# HDSC_HC32F480 register map
Vendor: HDSC Co.Ltd; Series: ARMCM4; File version: 1.2
CPU: CM0 r0p0, little endian, no MPU, no FPU, 3 interrupt priority bits
Registers are 16-bit, read-write, reset 0x0 unless marked. A register's access mark holds for its fields unless they carry their own. Offsets are from the block's base; [hi:lo] are bit positions; {n}, {i} and the like mark numbered series.

## EXMC
Base 0x40050000; alternate view of ETH
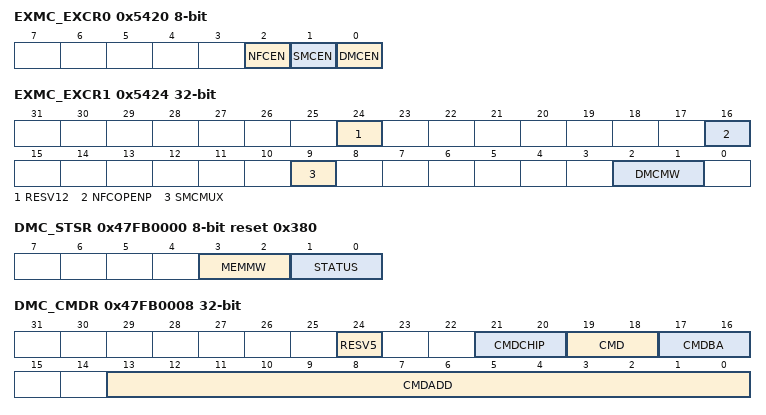
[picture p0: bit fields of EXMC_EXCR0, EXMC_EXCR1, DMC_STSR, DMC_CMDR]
0x5420 EXMC_EXCR0 8-bit
  [2] NFCEN, [1] SMCEN, [0] DMCEN
0x5424 EXMC_EXCR1 32-bit
  [24] RESV12, [16] NFCOPENP, [9] SMCMUX, [2:1] DMCMW
0x47FB0000 DMC_STSR 8-bit ro reset 0x380
  [3:2] MEMMW, [1:0] STATUS
0x47FB0004 DMC_STCR 8-bit wo
  [2:0] STCTL
0x47FB0008 DMC_CMDR 32-bit wo
  [24] RESV5 rw, [21:20] CMDCHIP, [19:18] CMD, [17:16] CMDBA, [13:0] CMDADD
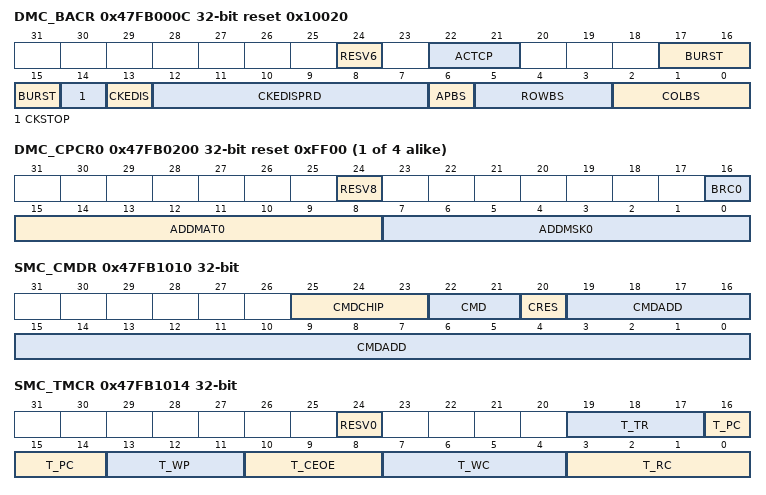
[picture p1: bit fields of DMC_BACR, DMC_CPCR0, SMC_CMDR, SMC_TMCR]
0x47FB000C DMC_BACR 32-bit reset 0x10020
  [24] RESV6, [22:21] ACTCP, [17:15] BURST, [14] CKSTOP, [13] CKEDIS, [12:7] CKEDISPRD, [6] APBS, [5:3] ROWBS, [2:0] COLBS
0x47FB0010 DMC_RFCR reset 0xA60
  [14:0] REFPRD
0x47FB0014 DMC_TMCR_T_CASL 8-bit reset 0x6
  [3:1] T_CASL
0x47FB0018 DMC_TMCR_T_DQSS 8-bit reset 0x1
  [1:0] T_DQSS
0x47FB001C DMC_TMCR_T_MRD 8-bit reset 0x2
  [6:0] T_MRD
0x47FB0020 DMC_TMCR_T_RAS 8-bit reset 0x7
  [3:0] T_RAS
0x47FB0024 DMC_TMCR_T_RC 8-bit reset 0xB
  [3:0] T_RC
0x47FB0028 DMC_TMCR_T_RCD 8-bit reset 0x1D
  [2:0] T_RCD
0x47FB002C DMC_TMCR_T_RFC 8-bit reset 0x212
  [4:0] T_RFC
0x47FB0030 DMC_TMCR_T_RP 8-bit reset 0x1D
  [2:0] T_RP
0x47FB0034 DMC_TMCR_T_RRD 8-bit reset 0x2
  [3:0] T_RRD
0x47FB0038 DMC_TMCR_T_WR 8-bit reset 0x3
  [2:0] T_WR
0x47FB003C DMC_TMCR_T_WTR 8-bit reset 0x2
  [2:0] T_WTR
0x47FB0040 DMC_TMCR_T_XP 8-bit reset 0x1
0x47FB0044 DMC_TMCR_T_XSR 8-bit reset 0xA
0x47FB0048 DMC_TMCR_T_ESR 8-bit reset 0x14
{0x47FB0200+4i} DMC_CPCR{i} 32-bit reset 0xFF00 (i=0..3)
  [24] RESV{i+8}, [16] BRC{i}, [15:8] ADDMAT{i}, [7:0] ADDMSK{i}
0x47FB0300 EXMC_EXSR1 8-bit ro
0x47FB1000 SMC_STSR 8-bit ro reset 0x1
  [0] STATUS
0x47FB1008 SMC_STCR0 8-bit wo
  [2] LPWIR
0x47FB100C SMC_STCR1 8-bit wo
  [2] LPWOR
0x47FB1010 SMC_CMDR 32-bit wo
  [25:23] CMDCHIP, [22:21] CMD, [20] CRES, [19:0] CMDADD
0x47FB1014 SMC_TMCR 32-bit wo
  [24] RESV0 rw, [19:17] T_TR, [16:14] T_PC, [13:11] T_WP, [10:8] T_CEOE, [7:4] T_WC, [3:0] T_RC
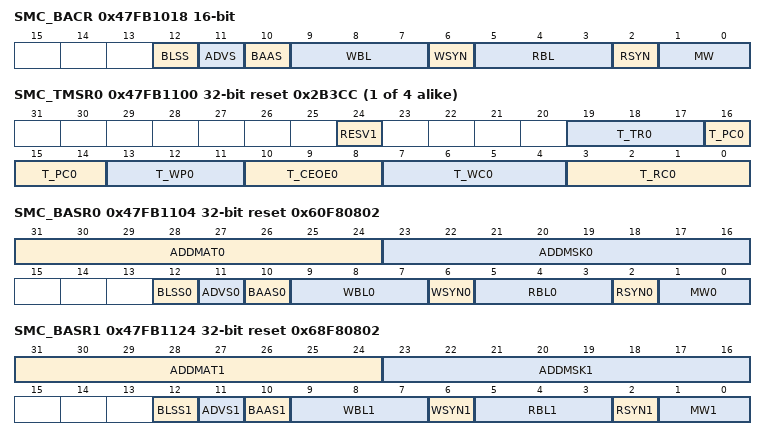
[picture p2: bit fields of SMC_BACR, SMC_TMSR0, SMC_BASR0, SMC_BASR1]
0x47FB1018 SMC_BACR wo
  [12] BLSS, [11] ADVS, [10] BAAS, [9:7] WBL, [6] WSYN, [5:3] RBL, [2] RSYN, [1:0] MW
0x47FB1020 SMC_RFCR 8-bit
  [3:0] REFPRD
{0x47FB1100+0x20*i} SMC_TMSR{i} 32-bit ro reset 0x2B3CC (i=0..3)
  [24] RESV{i+1} rw, [19:17] T_TR{i}, [16:14] T_PC{i}, [13:11] T_WP{i}, [10:8] T_CEOE{i}, [7:4] T_WC{i}, [3:0] T_RC{i}
0x47FB1104 SMC_BASR0 32-bit ro reset 0x60F80802
  [31:24] ADDMAT0, [23:16] ADDMSK0, [12] BLSS0, [11] ADVS0, [10] BAAS0, [9:7] WBL0, [6] WSYN0, [5:3] RBL0, [2] RSYN0, [1:0] MW0
0x47FB1124 SMC_BASR1 32-bit ro reset 0x68F80802
  [31:24] ADDMAT1, [23:16] ADDMSK1, [12] BLSS1, [11] ADVS1, [10] BAAS1, [9:7] WBL1, [6] WSYN1, [5:3] RBL1, [2] RSYN1, [1:0] MW1
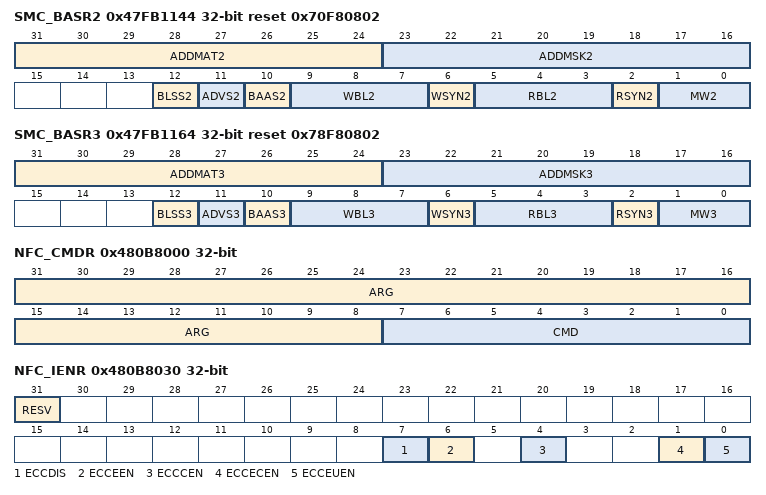
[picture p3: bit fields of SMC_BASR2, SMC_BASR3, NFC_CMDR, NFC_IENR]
0x47FB1144 SMC_BASR2 32-bit ro reset 0x70F80802
  [31:24] ADDMAT2, [23:16] ADDMSK2, [12] BLSS2, [11] ADVS2, [10] BAAS2, [9:7] WBL2, [6] WSYN2, [5:3] RBL2, [2] RSYN2, [1:0] MW2
0x47FB1164 SMC_BASR3 32-bit ro reset 0x78F80802
  [31:24] ADDMAT3, [23:16] ADDMSK3, [12] BLSS3, [11] ADVS3, [10] BAAS3, [9:7] WBL3, [6] WSYN3, [5:3] RBL3, [2] RSYN3, [1:0] MW3
0x47FB1200 EXMC_EXSR0 8-bit ro
  [0] ECCBSY
0x480B0000 NFC_DATR_BASE 32-bit
0x480B8000 NFC_CMDR 32-bit
  [31:8] ARG, [7:0] CMD
0x480B8004 NFC_IDXR0 32-bit
0x480B8030 NFC_IENR 32-bit
  [31] RESV, [7] ECCDIS, [6] ECCEEN, [4] ECCCEN, [1] ECCECEN, [0] ECCEUEN
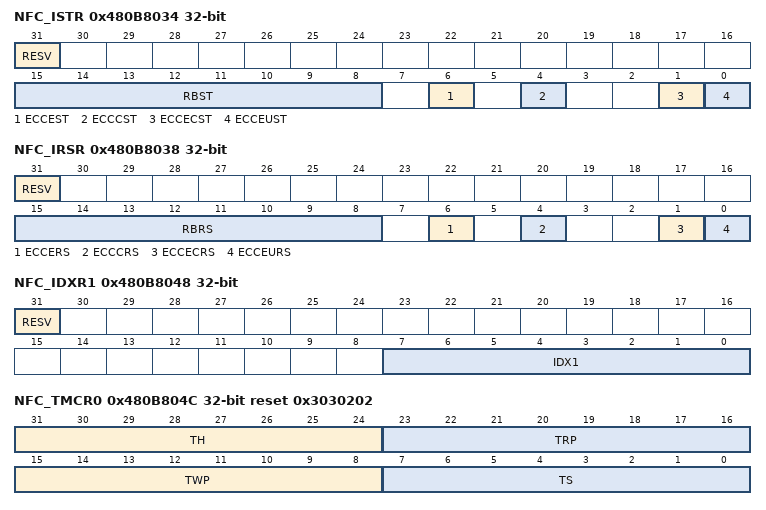
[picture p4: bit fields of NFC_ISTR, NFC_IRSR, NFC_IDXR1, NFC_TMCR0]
0x480B8034 NFC_ISTR 32-bit
  [31] RESV, [15:8] RBST, [6] ECCEST, [4] ECCCST, [1] ECCECST, [0] ECCEUST
0x480B8038 NFC_IRSR 32-bit
  [31] RESV, [15:8] RBRS, [6] ECCERS, [4] ECCCRS, [1] ECCECRS, [0] ECCEURS
0x480B8048 NFC_IDXR1 32-bit
  [31] RESV, [7:0] IDX1
0x480B804C NFC_TMCR0 32-bit reset 0x3030202
  [31:24] TH, [23:16] TRP, [15:8] TWP, [7:0] TS
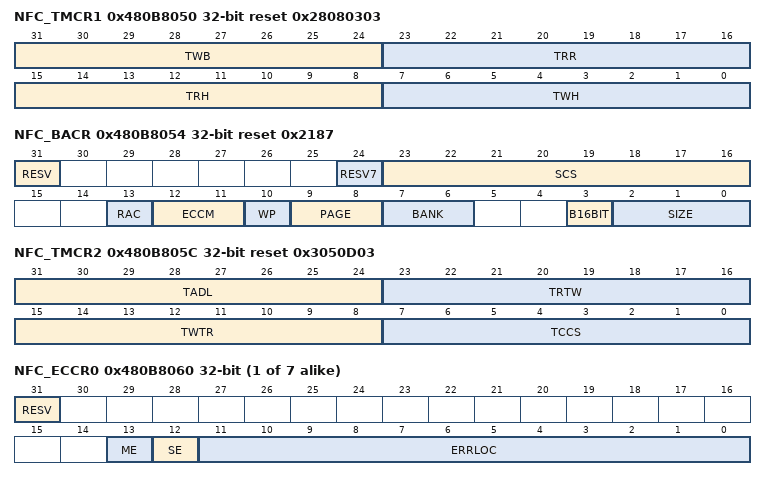
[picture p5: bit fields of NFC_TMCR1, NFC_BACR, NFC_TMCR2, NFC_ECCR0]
0x480B8050 NFC_TMCR1 32-bit reset 0x28080303
  [31:24] TWB, [23:16] TRR, [15:8] TRH, [7:0] TWH
0x480B8054 NFC_BACR 32-bit reset 0x2187
  [31] RESV, [24] RESV7, [23:16] SCS, [13] RAC, [12:11] ECCM, [10] WP, [9:8] PAGE, [7:6] BANK, [3] B16BIT, [2:0] SIZE
0x480B805C NFC_TMCR2 32-bit reset 0x3050D03
  [31:24] TADL, [23:16] TRTW, [15:8] TWTR, [7:0] TCCS
{0x480B8060+4i} NFC_ECCR{i} 32-bit ro (i=0..6)
  [31] RESV rw, [13] ME, [12] SE, [11:0] ERRLOC
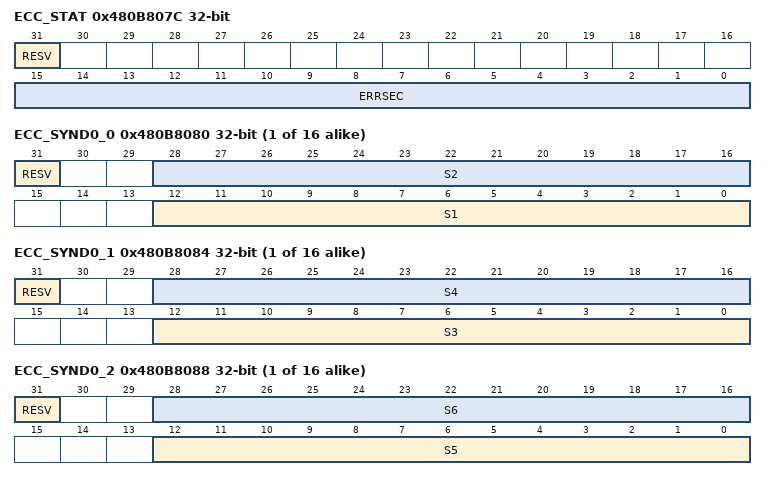
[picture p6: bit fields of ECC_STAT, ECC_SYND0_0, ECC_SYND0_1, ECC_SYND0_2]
0x480B807C ECC_STAT 32-bit ro
  [31] RESV rw, [15:0] ERRSEC
{0x480B8080+0x10*i} ECC_SYND{i}_0 32-bit ro (i=0..15)
  [31] RESV rw, [28:16] S2, [12:0] S1
{0x480B8084+0x10*i} ECC_SYND{i}_1 32-bit ro (i=0..15)
  [31] RESV rw, [28:16] S4, [12:0] S3
{0x480B8088+0x10*i} ECC_SYND{i}_2 32-bit ro (i=0..15)
  [31] RESV rw, [28:16] S6, [12:0] S5
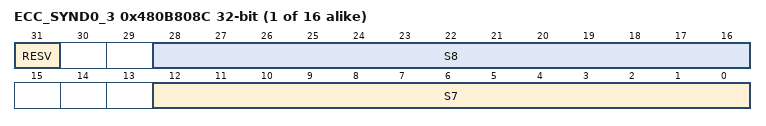
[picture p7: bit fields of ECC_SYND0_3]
{0x480B808C+0x10*i} ECC_SYND{i}_3 32-bit ro (i=0..15)
  [31] RESV rw, [28:16] S8, [12:0] S7
